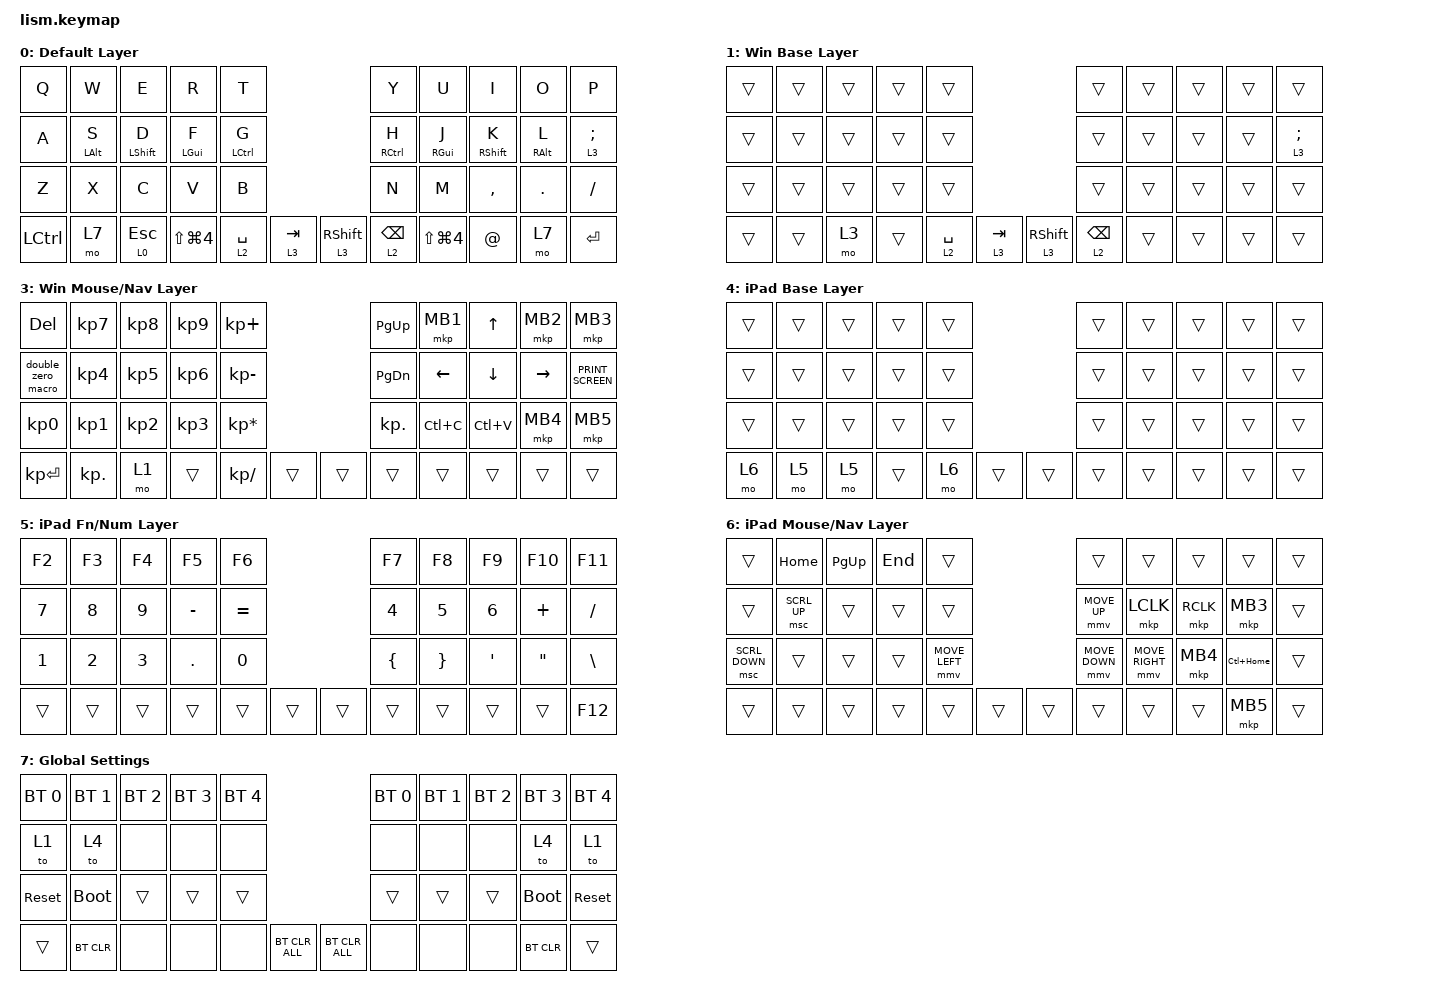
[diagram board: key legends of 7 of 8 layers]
#define ZMK_POINTING_DEFAULT_SCRL_VAL 200

#include <dt-bindings/zmk/mouse.h>
#include <behaviors.dtsi>
#include <dt-bindings/zmk/bt.h>
#include <dt-bindings/zmk/keys.h>
#include <dt-bindings/zmk/pointing.h>

// Mod-Tap/Layer-Tap の設定

&mt {
    tapping-term-ms = <300>;
    flavor = "balanced";
};

&lt { quick-tap-ms = <300>; };

/ {
    macros {
        emoji: emoji_macro {
            compatible = "zmk,behavior-macro";
            label = "EMOJI";
            #binding-cells = <0>;
            bindings =
                <&macro_press>,
                <&kp CAPSLOCK>,
                <&macro_tap>,
                <&kp E>,
                <&macro_release>,
                <&kp CAPSLOCK>;
        };

        // 「00」を入力するマクロ

        double_zero: double_zero_macro {
            compatible = "zmk,behavior-macro";
            label = "DBL_0";
            #binding-cells = <0>;
            bindings =
                <&macro_press>,
                <&kp KP_0>,
                <&macro_release>,
                <&kp KP_0>,
                <&macro_press>,
                <&kp KP_0>,
                <&macro_release>,
                <&kp KP_0>;
        };
    };

    behaviors {
        encoder_msc: sensor_rotate_msc {
            compatible = "zmk,behavior-sensor-rotate-var";
            #sensor-binding-cells = <2>;
            bindings = <&msc>, <&msc>;

            tap-ms = <20>;
        };

        encoder_kp: sensor_rotate_kp {
            compatible = "zmk,behavior-sensor-rotate-var";
            #sensor-binding-cells = <2>;
            bindings = <&kp>, <&kp>;
        };
    };

    keymap {
        compatible = "zmk,keymap";

        // L0: Windows/iPad 共通のベースレイヤー (L7へのアクセスキーを変更)

        default_layer {
            display-name = "Default Layer";
            bindings = <
&kp Q      &kp W       &kp E         &kp R           &kp T                                   &kp Y            &kp U           &kp I         &kp O       &kp P
&kp A      &mt LALT S  &mt LSHIFT D  &mt LGUI F      &mt LCTRL G                             &mt RCTRL H      &mt RGUI J      &mt RSHIFT K  &mt RALT L  &lt 3 SEMI
&kp Z      &kp X       &kp C         &kp V           &kp B                                   &kp N            &kp M           &kp COMMA     &kp DOT     &kp SLASH
&kp LCTRL  &mo 7       &lt 0 ESC     &kp LS(LG(N4))  &lt 2 SPACE  &lt 3 TAB    &lt 3 RSHIFT  &lt 2 BACKSPACE  &kp LS(LG(N4))  &kp AT_SIGN   &mo 7       &kp ENTER
            >;

            sensor-bindings = <&encoder_msc SCRL_DOWN SCRL_UP>;
        };

        // L1: Windows ベースレイヤー

        layer_1 {
            display-name = "Win Base Layer";
            bindings = <
&trans  &trans  &trans  &trans  &trans                                  &trans           &trans  &trans  &trans  &trans
&trans  &trans  &trans  &trans  &trans                                  &trans           &trans  &trans  &trans  &lt 3 SEMI
&trans  &trans  &trans  &trans  &trans                                  &trans           &trans  &trans  &trans  &trans
&trans  &trans  &mo 3   &trans  &lt 2 SPACE  &lt 3 TAB    &lt 3 RSHIFT  &lt 2 BACKSPACE  &trans  &trans  &trans  &trans
            >;

            sensor-bindings = <&encoder_msc SCRL_LEFT SCRL_RIGHT>;
        };

        // L2: Windows Fn / 数字 / 記号レイヤー (Keyball L1/L2の機能を統合)

        layer_2 {
            display-name = "Win Fn/Num Layer";
            bindings = <
&kp F2    &kp F3             &kp F4     &kp F5        &kp F6                         &kp F7            &kp F8            &kp F9                &kp F10                &kp F11
&kp EXCL  &kp DOUBLE_QUOTES  &kp HASH   &kp DOLLAR    &kp PERCENT                    &kp AMPERSAND     &kp SINGLE_QUOTE  &kp LEFT_PARENTHESIS  &kp RIGHT_PARENTHESIS  &kp TILDE
&kp F1    &kp SEMI           &kp COLON  &kp LEFT_GUI  &kp PIPE                       &kp LBRC          &kp RBRC          &kp BSLH              &kp AT_SIGN            &kp F12
&trans    &trans             &trans     &trans        &trans       &trans    &trans  &trans            &trans            &trans
            >;

            sensor-bindings = <&encoder_kp C_VOL_UP C_VOL_DN>;
        };

        // L3: Windows マウス / ナビゲーションレイヤー (Keyball L2のマウス機能を移植)

        layer_3 {
            display-name = "Win Mouse/Nav Layer";
            bindings = <
&kp DEL             &kp KP_7         &kp KP_8         &kp KP_9         &kp KP_PLUS                        &kp PG_UP      &mkp MB1   &kp UP     &mkp MB2   &mkp MB3
&macro double_zero  &kp KP_4         &kp KP_5         &kp KP_6         &kp KP_MINUS                       &kp PG_DN      &kp LEFT   &kp DOWN   &kp RIGHT  &kp PRINT_SCREEN
&kp KP_0            &kp KP_1         &kp KP_2         &kp KP_3         &kp KP_MULTIPLY                    &kp KP_DOT     &kp LC(C)  &kp LC(V)  &mkp MB4   &mkp MB5
&kp KP_ENTER        &kp KP_DOT       &mo 1            &trans           &kp KP_DIVIDE    &trans    &trans  &trans         &trans     &trans     &trans     &trans
            >;

            sensor-bindings = <&encoder_msc SCRL_DOWN SCRL_UP>;
        };

        // L4: iPad ベースレイヤー

        layer_4 {
            display-name = "iPad Base Layer";
            bindings = <
&trans  &trans  &trans  &trans  &trans                    &trans  &trans  &trans  &trans  &trans
&trans  &trans  &trans  &trans  &trans                    &trans  &trans  &trans  &trans  &trans
&trans  &trans  &trans  &trans  &trans                    &trans  &trans  &trans  &trans  &trans
&mo 6   &mo 5   &mo 5   &trans  &mo 6   &trans    &trans  &trans  &trans  &trans  &trans  &trans
            >;

            sensor-bindings = <&encoder_kp C_VOL_UP C_VOL_DN>;
        };

        // L5: iPad Fn / 数字 / 記号レイヤー (L2をベースに、LCMDなどを活用)

        layer_5 {
            display-name = "iPad Fn/Num Layer";
            bindings = <
&kp F2  &kp F3  &kp F4  &kp F5     &kp F6                       &kp F7    &kp F8    &kp F9   &kp F10   &kp F11
&kp N7  &kp N8  &kp N9  &kp MINUS  &kp EQUAL                    &kp N4    &kp N5    &kp N6   &kp PLUS  &kp SLASH
&kp N1  &kp N2  &kp N3  &kp DOT    &kp N0                       &kp LBRC  &kp RBRC  &kp SQT  &kp DQT   &kp BSLH
&trans  &trans  &trans  &trans     &trans     &trans    &trans  &trans    &trans    &trans   &trans    &kp F12
            >;
        };

        // L6: iPad マウス / ナビゲーションレイヤー (L3をベースに、iPad特有のキーを追加)

        layer_6 {
            display-name = "iPad Mouse/Nav Layer";
            bindings = <
&trans          &kp HOME      &kp PG_UP  &kp END  &trans                            &trans          &trans           &trans     &trans      &trans
&trans          &msc SCRL_UP  &trans     &trans   &trans                            &mmv MOVE_UP    &mkp LCLK        &mkp RCLK  &mkp MB3    &trans
&msc SCRL_DOWN  &trans        &trans     &trans   &mmv MOVE_LEFT                    &mmv MOVE_DOWN  &mmv MOVE_RIGHT  &mkp MB4   &kp LC(HOME)  &trans
&trans          &trans        &trans     &trans   &trans          &trans    &trans  &trans          &trans           &trans     &mkp MB5    &trans
            >;

            sensor-bindings = <&encoder_msc SCRL_DOWN SCRL_UP>;
        };

        // L7: 全体設定/OS・BT切り替え (旧 L4の機能を移動・統合)

        layer_7 {
            display-name = "Global Settings";
            bindings = <
&bt BT_SEL 0  &bt BT_SEL 1  &bt BT_SEL 2  &bt BT_SEL 3  &bt BT_SEL 4                                    &bt BT_SEL 0  &bt BT_SEL 1  &bt BT_SEL 2  &bt BT_SEL 3  &bt BT_SEL 4
&to 1         &to 4         &none         &none         &none                                           &none         &none         &none         &to 4         &to 1
&sys_reset    &bootloader   &trans        &trans        &trans                                          &trans        &trans        &trans        &bootloader   &sys_reset
&trans        &bt BT_CLR    &none         &none         &none         &bt BT_CLR_ALL    &bt BT_CLR_ALL  &none         &none         &none         &bt BT_CLR    &trans
            >;
        };
    };
}; // keymap ノード終了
